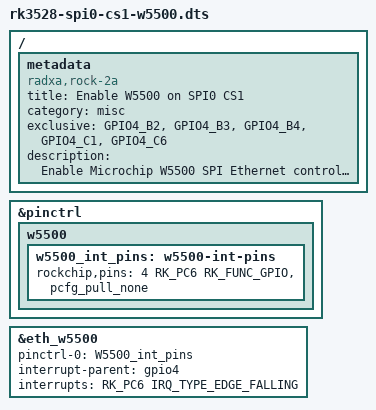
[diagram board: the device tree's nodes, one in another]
#define W5500_SPI spi0
#define SPIDEV_NUM 1
#include "W5500.dtsi"

/ {
	metadata {
		title = "Enable W5500 on SPI0 CS1";
		compatible = "radxa,rock-2a", "radxa,rock-2f", "radxa,medge-rk3528a-io";
		category = "misc";
		exclusive = "GPIO4_B2", "GPIO4_B3", "GPIO4_B4", "GPIO4_C1", "GPIO4_C6";
		description = "Enable Microchip W5500 SPI Ethernet controller on SPI0 CS1.
INT=15";
	};
};

&pinctrl {
	w5500 {
		w5500_int_pins: w5500-int-pins {
			rockchip,pins = <4 RK_PC6 RK_FUNC_GPIO &pcfg_pull_none>;
		};
	};
};

&eth_w5500 {
	pinctrl-names = "default";
	pinctrl-0 = <&W5500_int_pins>;
	interrupt-parent = <&gpio4>;
	interrupts = <RK_PC6 IRQ_TYPE_EDGE_FALLING>;
};
